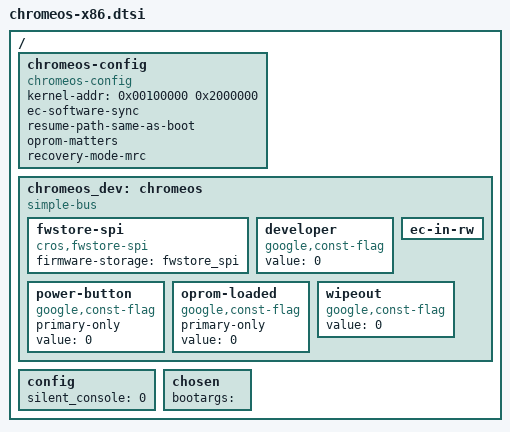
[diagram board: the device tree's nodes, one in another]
// SPDX-License-Identifier: GPL-2.0+
/*
 * Chromium OS-specific options for x86
 *
 * Copyright 2018 Google LLC
 */

#include <dt-bindings/gpio/gpio.h>
#include <dt-bindings/gpio/x86-gpio.h>
#include <asm/arch-apollolake/gpio.h>

/ {
	chromeos-config {
		compatible = "chromeos-config";
		u-boot,dm-spl;
		u-boot,dm-vpl;
		/* Kernel start address and size */
		kernel-addr = /bits/ 64 <0x00100000 0x2000000>;
		ec-software-sync;
		resume-path-same-as-boot;
		oprom-matters;
		recovery-mode-mrc;
	};

	chromeos_dev: chromeos {
		u-boot,dm-spl;
		u-boot,dm-vpl;
		compatible = "simple-bus";
		fwstore-spi {
			u-boot,dm-spl;
			u-boot,dm-vpl;
			compatible = "cros,fwstore-spi";
			firmware-storage = <&fwstore_spi>;
		};
		developer {
			u-boot,dm-spl;
			u-boot,dm-vpl;
			compatible = "google,const-flag";
			value = <0>;
		};
		power-button {
			u-boot,dm-spl;
			u-boot,dm-vpl;
			compatible = "google,const-flag";
			primary-only;
			value = <0>;
		};
		oprom-loaded {
			u-boot,dm-spl;
			u-boot,dm-vpl;
			compatible = "google,const-flag";
			primary-only;
			value = <0>;
		};

		/* Set up ec-in-rw in board .dts */
		ec-in-rw {
		};

		wipeout {
			u-boot,dm-spl;
			u-boot,dm-vpl;
			compatible = "google,const-flag";
			value = <0>;
		};
	};

	config {
		silent_console = <0>;
	};

	chosen {
		bootargs = "";
	};
};
